# ADSP-2183xW_LPC register map
Vendor: Analog Devices; Series: ADSP-2183xW_LPC; File version: 3.0.3.517
CPU: 
Registers are 32-bit, read-write, reset 0x0 unless marked. A register's access mark holds for its fields unless they carry their own. Offsets are from the block's base; [hi:lo] are bit positions; {n}, {i} and the like mark numbered series.

## Miscellaneous_Registers
Base 0x31114000
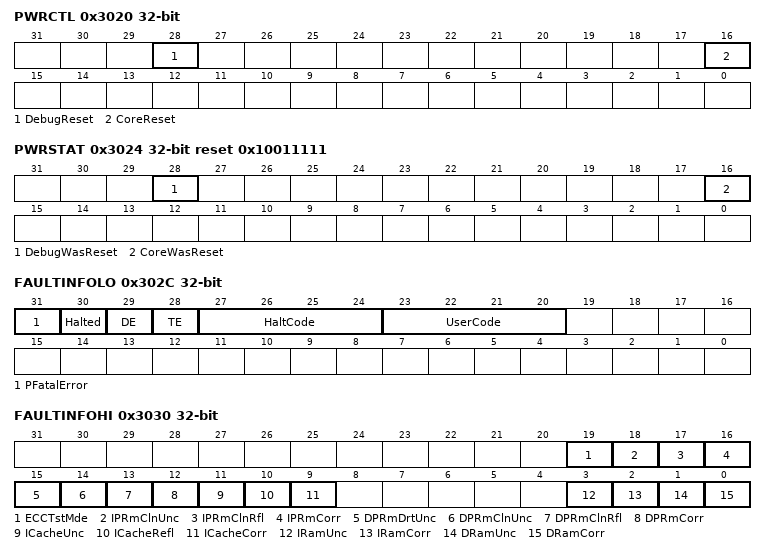
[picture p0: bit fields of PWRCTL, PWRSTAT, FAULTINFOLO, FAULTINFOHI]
0x3020 PWRCTL
  [28] DebugReset range 0x00000000..0x00000001, [16] CoreReset range 0x00000000..0x00000001
0x3024 PWRSTAT reset 0x10011111
  [28] DebugWasReset range 0x00000000..0x00000001, [16] CoreWasReset range 0x00000000..0x00000001
0x3028 ERISTAT
  [0] WRISUC ro
0x302C FAULTINFOLO
  [31] PFatalError ro, [30] Halted ro, [29] DE ro, [28] TE ro, [27:24] HaltCode ro, [23:20] UserCode range 0x00000000..0x0000000F
0x3030 FAULTINFOHI
  [19] ECCTstMde ro, [18] IPRmClnUnc ro, [17] IPRmClnRfl ro, [16] IPRmCorr ro, [15] DPRmDrtUnc ro, [14] DPRmClnUnc ro, [13] DPRmClnRfl ro, [12] DPRmCorr ro, [11] ICacheUnc ro, [10] ICacheRefl ro, [9] ICacheCorr ro, [3] IRamUnc ro, [2] IRamCorr ro, [1] DRamUnc ro, [0] DRamCorr ro

## Trax_Registers
Base 0x31114000
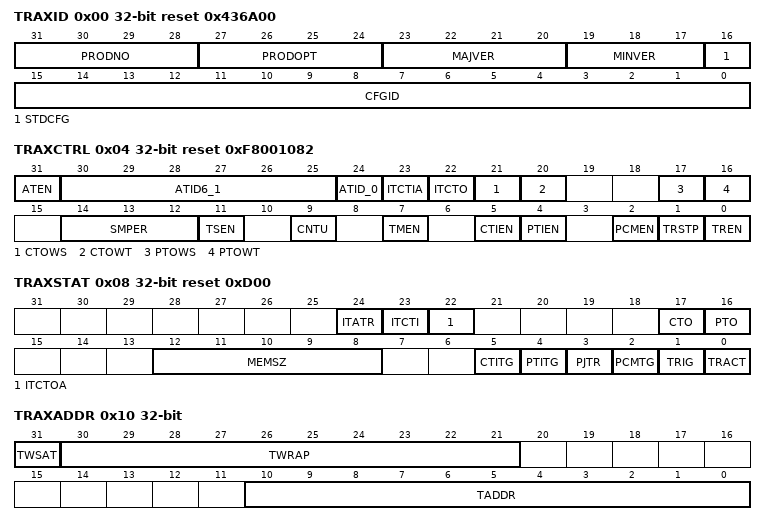
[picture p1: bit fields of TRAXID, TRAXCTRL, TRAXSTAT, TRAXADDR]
0x00 TRAXID reset 0x436A00
  [31:28] PRODNO ro, [27:24] PRODOPT ro, [23:20] MAJVER ro, [19:17] MINVER ro, [16] STDCFG ro, [15:0] CFGID ro
0x04 TRAXCTRL reset 0xF8001082
  [31] ATEN range 0x00000000..0x00000001
  [30:25] ATID6_1 range 0x00000000..0x0000003F
  [24] ATID_0 range 0x00000000..0x00000001
  [23] ITCTIA range 0x00000000..0x00000001
  [22] ITCTO range 0x00000000..0x00000001
  [21] CTOWS range 0x00000000..0x00000001
  [20] CTOWT range 0x00000000..0x00000001
  [17] PTOWS range 0x00000000..0x00000001
  [16] PTOWT range 0x00000000..0x00000001
  [14:12] SMPER
    0=SMNone; 1=SMPER256; 2=SMPER128; 3=SMPER64; 4=SMPER32; 5=SMPER16; 6=SMPER8
  [11] TSEN range 0x00000000..0x00000001
  [9] CNTU range 0x00000000..0x00000001
  [7] TMEN range 0x00000000..0x00000001
  [5] CTIEN range 0x00000000..0x00000001
  [4] PTIEN range 0x00000000..0x00000001
  [2] PCMEN range 0x00000000..0x00000001
  [1] TRSTP range 0x00000000..0x00000001
  [0] TREN range 0x00000000..0x00000001
0x08 TRAXSTAT reset 0xD00
  [24] ITATR ro, [23] ITCTI ro, [22] ITCTOA ro, [17] CTO ro, [16] PTO ro, [12:8] MEMSZ ro, [5] CTITG ro, [4] PTITG ro, [3] PJTR ro, [2] PCMTG ro, [1] TRIG ro, [0] TRACT ro
0x0C TRAXDATA
  [31:0] TRAXDATA range 0x00000000..0xFFFFFFFF
0x10 TRAXADDR
  [31] TWSAT range 0x00000000..0x00000001, [30:21] TWRAP range 0x00000000..0x000003FF, [10:0] TADDR range 0x00000000..0x000007FF
0x14 TRIGGERPC
  [31:0] TRIGGERPC range 0x00000000..0xFFFFFFFF
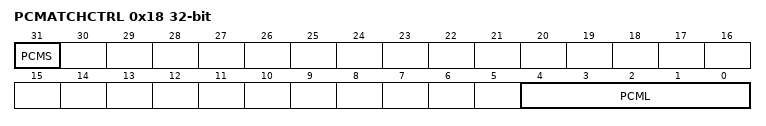
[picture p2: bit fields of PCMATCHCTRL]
0x18 PCMATCHCTRL
  [31] PCMS range 0x00000000..0x00000001, [4:0] PCML range 0x00000000..0x0000001F
0x1C DELAYCNT
  [23:0] DELAYCNT range 0x00000000..0x00FFFFFF
0x20 MEMADDRSTART
  [10:0] MEMADDRSTART range 0x00000000..0x000007FF
0x24 MEMADDREND reset 0x7FF
  [10:0] MEMADDREND range 0x00000000..0x000007FF
0x40 EXTTIMELO
  [31:0] EXTTIMELO ro
0x44 EXTTIMEHI
  [31:0] EXTTIMEHI ro

## CSAHBAP
Base 0x31118000
{0x0+4i} DAR{i} (i=0..255) — Direct Access Register {i}.
  [31:0] Data range 0x00000000..0xFFFFFFFF
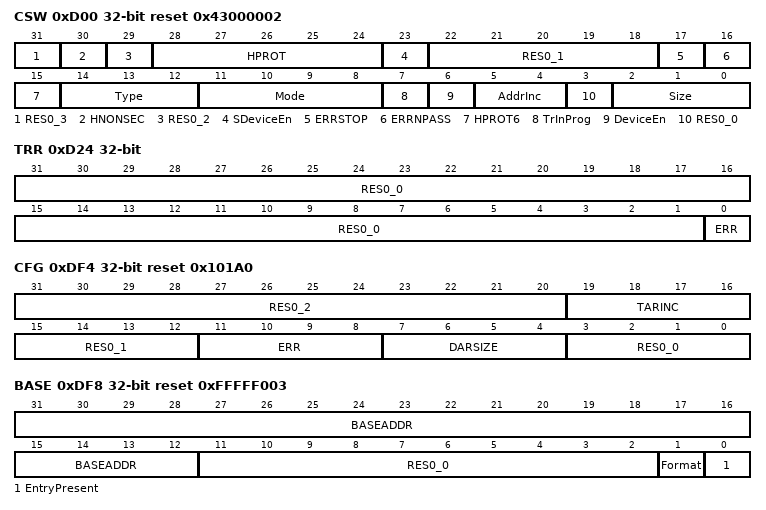
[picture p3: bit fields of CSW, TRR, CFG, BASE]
0xD00 CSW reset 0x43000002 — Control Status Word register.
  [31] RES0_3 range 0x00000000..0x00000001, [30] HNONSEC range 0x00000000..0x00000001, [29] RES0_2 range 0x00000000..0x00000001, [28:24] HPROT range 0x00000000..0x0000001F, [23] SDeviceEn ro, [22:18] RES0_1 range 0x00000000..0x0000001F, [17] ERRSTOP range 0x00000000..0x00000001, [16] ERRNPASS range 0x00000000..0x00000001, [15] HPROT6 range 0x00000000..0x00000001, [14:12] Type ro, [11:8] Mode ro, [7] TrInProg ro, [6] DeviceEn ro, [5:4] AddrInc range 0x00000000..0x00000003, [3] RES0_0 range 0x00000000..0x00000001, [2:0] Size range 0x00000000..0x00000007
0xD04 TAR — Transfer Address Register.
  [31:0] Address range 0x00000000..0xFFFFFFFF
0xD0C DRW — Data Read/Write register.
  [31:0] Data range 0x00000000..0xFFFFFFFF
{0xD10+4i} BD{i} (i=0..3) — Banked Data register {i}.
  [31:0] Data range 0x00000000..0xFFFFFFFF
0xD24 TRR — Transfer Response Register.
  [31:1] RES0_0 range 0x00000000..0x7FFFFFFF, [0] ERR range 0x00000000..0x00000001
0xDF4 CFG reset 0x101A0 — Configuration register.
  [31:20] RES0_2 ro, [19:16] TARINC ro, [15:12] RES0_1 ro, [11:8] ERR ro, [7:4] DARSIZE ro, [3:0] RES0_0 ro
0xDF8 BASE reset 0xFFFFF003 — Debug Base Address register.
  [31:12] BASEADDR ro, [11:2] RES0_0 ro, [1] Format ro, [0] EntryPresent ro
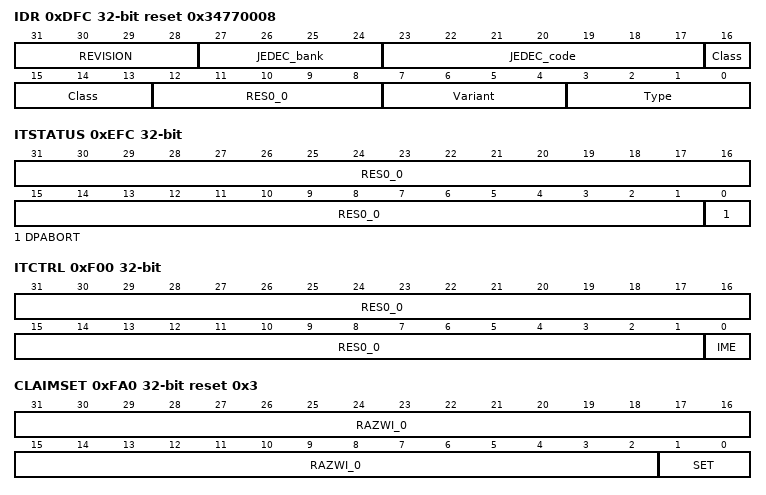
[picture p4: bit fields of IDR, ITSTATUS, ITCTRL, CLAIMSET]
0xDFC IDR reset 0x34770008 — Identification Register.
  [31:28] REVISION ro, [27:24] JEDEC_bank ro, [23:17] JEDEC_code ro, [16:13] Class ro, [12:8] RES0_0 ro, [7:4] Variant ro, [3:0] Type ro
0xEFC ITSTATUS — Integration Test Status register.
  [31:1] RES0_0 range 0x00000000..0x7FFFFFFF, [0] DPABORT ro
0xF00 ITCTRL — Integration Mode Control Register.
  [31:1] RES0_0 range 0x00000000..0x7FFFFFFF, [0] IME range 0x00000000..0x00000001
0xFA0 CLAIMSET reset 0x3 — Claim Tag Set Register.
  [31:2] RAZWI_0 range 0x00000000..0x3FFFFFFF, [1:0] SET range 0x00000000..0x00000003
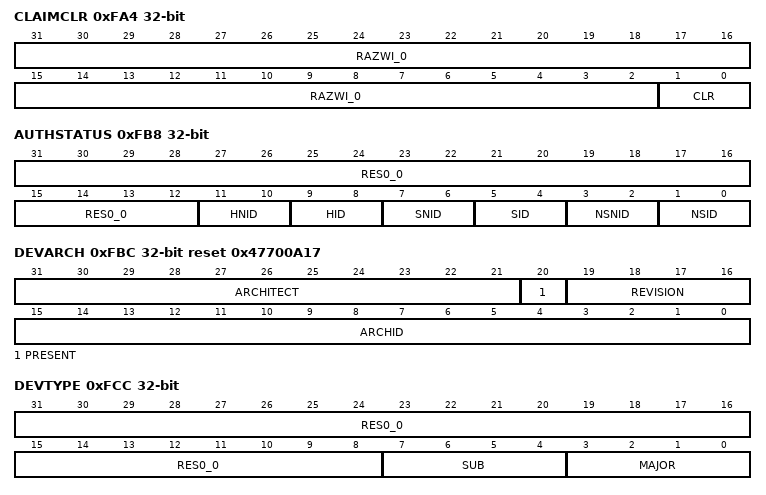
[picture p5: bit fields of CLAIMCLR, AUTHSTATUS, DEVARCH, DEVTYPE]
0xFA4 CLAIMCLR — Claim Tag Clear Register.
  [31:2] RAZWI_0 range 0x00000000..0x3FFFFFFF, [1:0] CLR range 0x00000000..0x00000003
0xFB8 AUTHSTATUS — Authentication Status Register.
  [31:12] RES0_0 ro, [11:10] HNID ro, [9:8] HID ro, [7:6] SNID ro, [5:4] SID ro, [3:2] NSNID ro, [1:0] NSID ro
0xFBC DEVARCH reset 0x47700A17 — Device Architecture Register.
  [31:21] ARCHITECT ro, [20] PRESENT ro, [19:16] REVISION ro, [15:0] ARCHID ro
0xFCC DEVTYPE — Device Type Identifier Register.
  [31:8] RES0_0 ro, [7:4] SUB ro, [3:0] MAJOR ro
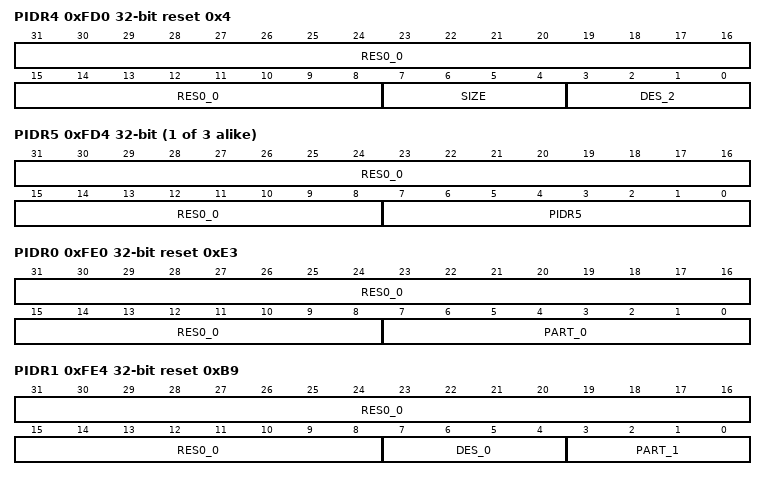
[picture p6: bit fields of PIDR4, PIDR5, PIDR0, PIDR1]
0xFD0 PIDR4 reset 0x4 — Peripheral Identification Register 4.
  [31:8] RES0_0 ro, [7:4] SIZE ro, [3:0] DES_2 ro
{0xFC0+4i} PIDR{i} (i=5..7) — Peripheral Identification Register {i}.
  [31:8] RES0_0 ro, [7:0] PIDR{i} ro
0xFE0 PIDR0 reset 0xE3 — Peripheral Identification Register 0.
  [31:8] RES0_0 ro, [7:0] PART_0 ro
0xFE4 PIDR1 reset 0xB9 — Peripheral Identification Register 1.
  [31:8] RES0_0 ro, [7:4] DES_0 ro, [3:0] PART_1 ro
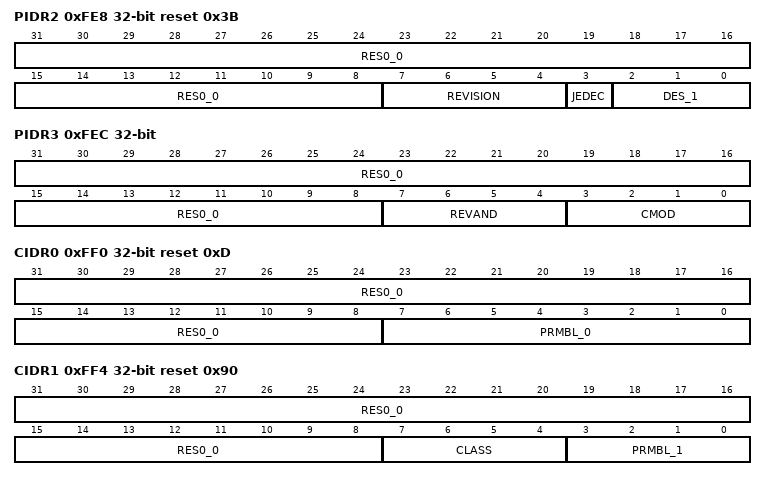
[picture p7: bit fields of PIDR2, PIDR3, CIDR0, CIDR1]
0xFE8 PIDR2 reset 0x3B — Peripheral Identification Register 2.
  [31:8] RES0_0 ro, [7:4] REVISION ro, [3] JEDEC ro, [2:0] DES_1 ro
0xFEC PIDR3 — Peripheral Identification Register 3.
  [31:8] RES0_0 ro, [7:4] REVAND ro, [3:0] CMOD ro
0xFF0 CIDR0 reset 0xD — Component Identification Register 0.
  [31:8] RES0_0 ro, [7:0] PRMBL_0 ro
0xFF4 CIDR1 reset 0x90 — Component Identification Register 1.
  [31:8] RES0_0 ro, [7:4] CLASS ro, [3:0] PRMBL_1 ro
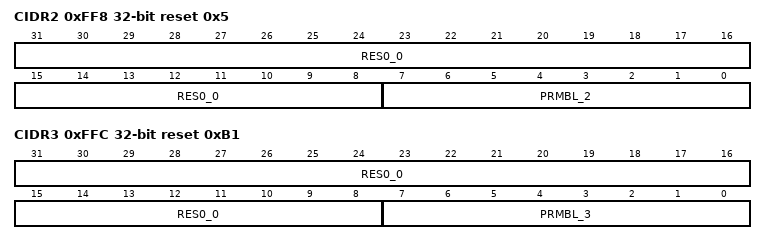
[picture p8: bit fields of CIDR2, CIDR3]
0xFF8 CIDR2 reset 0x5 — Component Identification Register 2.
  [31:8] RES0_0 ro, [7:0] PRMBL_2 ro
0xFFC CIDR3 reset 0xB1 — Component Identification Register 3.
  [31:8] RES0_0 ro, [7:0] PRMBL_3 ro

## TAPC
Base 0x31130000
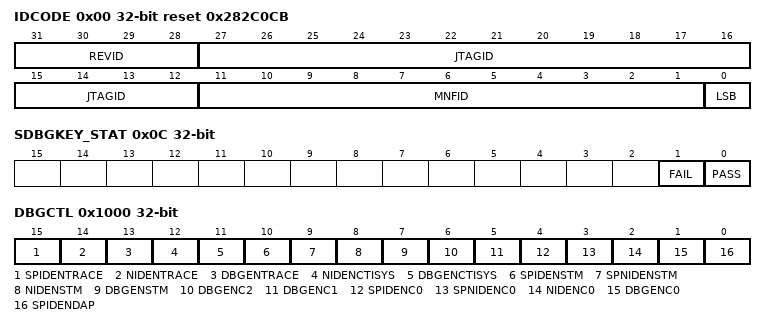
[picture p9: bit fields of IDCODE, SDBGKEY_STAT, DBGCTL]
0x00 IDCODE reset 0x282C0CB
  [31:28] REVID ro — Silicon Revision
  [27:12] JTAGID ro
  [11:1] MNFID ro — Manufacturer ID
  [0] LSB ro — IDCODE LSB
0x04 USERCODE
  [31:0] VALUE ro — USERCODE[31:0]
0x08 SDBGKEY_CTL — Secure Debug Key Control Register
  [0] VALID range 0x00000000..0x00000001 — SDBGKEY Valid bit
0x0C SDBGKEY_STAT — Secure Debug Key Status Register
  [1] FAIL ro — SDBGKEY MATCH FAILED
  [0] PASS ro — SDBGKEY MATCH PASSED
{0x10+4i} SDBGKEY{i} (i=0..7) — Secure Debug Key {i} Register
  [31:0] KEY_VALUE range 0x00000000..0xFFFFFFFF — KEY_VALUE[{32i+31}:{32i}] 256 BIT SDBGKEY
0x1000 DBGCTL — Debug Control Register
  [15] SPIDENTRACE range 0x00000000..0x00000001 — SPIDEN for Coresight Trace Modules
  [14] NIDENTRACE range 0x00000000..0x00000001 — NIDEN for Coresight Trace Modules
  [13] DBGENTRACE range 0x00000000..0x00000001 — DBGEN for Coresight Trace Modules
  [12] NIDENCTISYS range 0x00000000..0x00000001 — NIDEN for System CTI
  [11] DBGENCTISYS range 0x00000000..0x00000001 — DBGEN for System CTI
  [10] SPIDENSTM range 0x00000000..0x00000001 — SPIDEN for STM
  [9] SPNIDENSTM range 0x00000000..0x00000001 — SPNIDEN for STM
  [8] NIDENSTM range 0x00000000..0x00000001 — NIDEN for STM
  [7] DBGENSTM range 0x00000000..0x00000001 — DBGEN for STM
  [6] DBGENC2 range 0x00000000..0x00000001 — DBGEN for Core 2
  [5] DBGENC1 range 0x00000000..0x00000001 — DBGEN for Core 1
  [4] SPIDENC0 range 0x00000000..0x00000001 — SPIDEN for Core 0
  [3] SPNIDENC0 range 0x00000000..0x00000001 — SPNIDEN for Core 0
  [2] NIDENC0 range 0x00000000..0x00000001 — NIDEN for Core 0
  [1] DBGENC0 range 0x00000000..0x00000001 — DBGEN for Core 0
  [0] SPIDENDAP range 0x00000000..0x00000001 — SPIDEN for DAP
